# D1H.pdf register map
Vendor: Allwinner; Series: D1H.pdf; File version: 0.1
CPU: XuanTie C906 RISC-V CPU 0, little endian, MPU, FPU, double-precision FPU, 0 interrupt priority bits
Registers are 32-bit, read-write, reset 0x0 unless marked. A register's access mark holds for its fields unless they carry their own. Offsets are from the block's base; [hi:lo] are bit positions; lines under a group give offsets from that group; {n}, {i} and the like mark numbered series.

## TVD_TOP
Base 0x05C00000
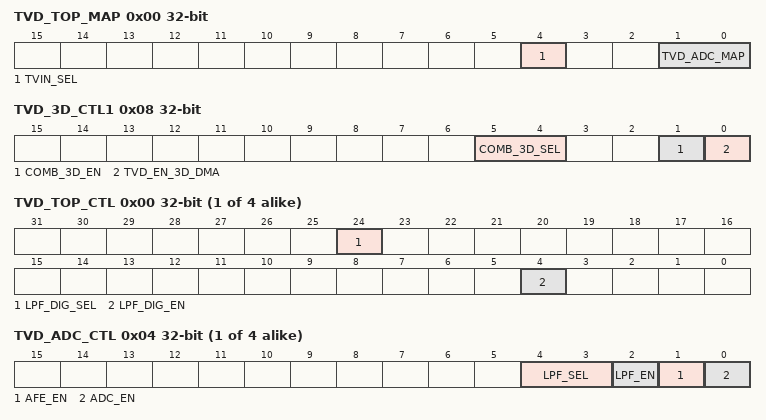
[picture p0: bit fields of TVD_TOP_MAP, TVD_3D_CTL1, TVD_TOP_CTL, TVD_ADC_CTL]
0x00 TVD_TOP_MAP
  [4] TVIN_SEL — TVIN Select 0:TVIN0 1:TVIN1
  [1:0] TVD_ADC_MAP — TVD ADC Map 01: CVBS_MODE Others: Reserved
    1=CVBS_MODE
0x08 TVD_3D_CTL1 — TVD 3D DMA CONTROL Register1
  [5:4] COMB_3D_SEL — Comb 3D Select 00: TVD0 Others: Reserved
    0=TVD0
  [1] COMB_3D_EN — Comb 3D Enable 0: Disable 1: Enable
    0=Disable; 1=Enable
  [0] TVD_EN_3D_DMA — TVD Enable 3D DMA 0: Disable 1: Enable Set 0x1 when enable 3D comb filter.
    0=Disable; 1=Enable Set 0x1 when enable 3D comb filter
0x0C TVD_3D_CTL2 — TVD 3D DMA CONTROL Register2
  [31:0] DRAM_TRIG — DRAM Trigger
0x10 TVD_3D_CTL3 — TVD 3D DMA CONTROL Register3
  [31:0] COMB_3D_ADDR0 — Comb 3D Address0
0x14 TVD_3D_CTL4 — TVD 3D DMA CONTROL Register4
  [31:0] COMB_3D_ADDR1 — Comb 3D Address1
0x18 TVD_3D_CTL5 — TVD 3D DMA CONTROL Register5
  [31:0] COMB_3D_SIZE
{0x24+0x20*i} _N[{i}] (i=0..3) group
  0x00 TVD_TOP_CTL — TVD TOP CONTROL Register
    [24] LPF_DIG_SEL — Low Pass Filter Digital Select 0: 6M 1: 8M
      0=_6M; 1=_8M
    [4] LPF_DIG_EN — Low Pass Filter Digital Enable 0: Disable 1: Enable
      0=Disable; 1=Enable
  0x04 TVD_ADC_CTL — TVD ADC CONTROL Register
    [4:3] LPF_SEL — Low Pass Filter Select 00: 11M 01: 16M
      0=_11M; 1=_16M
    [2] LPF_EN — Low Pass Filter Enable 0: Disable LPF circuit 1: Enable LPF circuit
      0=Disable LPF circuit; 1=Enable LPF circuit
    [1] AFE_EN — AFE Enable 0: Disable AFE circuit 1: Enable AFE circuit
      0=Disable AFE circuit; 1=Enable AFE circuit
    [0] ADC_EN — ADC Enable 0: Disable ADC circuit 1: Enable ADC circuit
      0=Disable ADC circuit; 1=Enable ADC circuit
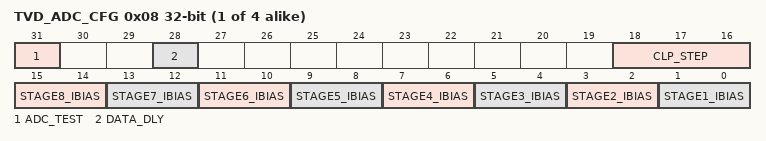
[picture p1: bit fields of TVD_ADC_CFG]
  0x08 TVD_ADC_CFG — TVD ADC CONFIGURATION Register
    [31] ADC_TEST — ADC Test Mode Configuration 0: Normal mode 1: For ADC test
      0=Normal_mode; 1=For (For ADC test)
    [28] DATA_DLY — Data Delay Configuration 0: No delay 1: Delay ADC output data for half circle
      0=No_delay; 1=Delay ADC output data for half circle
    [18:16] CLP_STEP — CLAMP Step Configuration DC level size step for up and down.
    [2n-1:2n-2] STAGE{n}_IBIAS (n=1..8) — Stage{n} Ibias Configuration

## TVE_TOP
Base 0x05600000
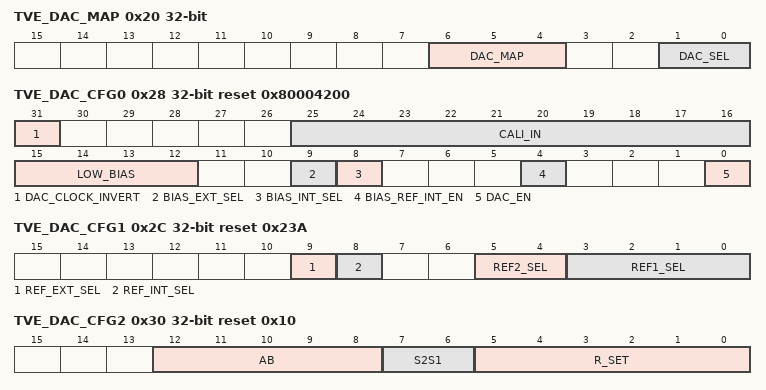
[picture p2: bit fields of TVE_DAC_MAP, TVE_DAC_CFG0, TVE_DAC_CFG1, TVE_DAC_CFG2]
0x20 TVE_DAC_MAP — TV Encoder DAC MAP Register
  [6:4] DAC_MAP — 000: OUT0 Others: Reserved
    0=OUT0
  [1:0] DAC_SEL — 00: Reserved 01: TVE0 10: Reserved 11: Reserved
    1=TVE0
0x24 TVE_DAC_STATUS — TV Encoder DAC STAUTS Register
  [1:0] DAC_STATUS ro — 00: Unconnected 01: Connected 11: Short to ground 10: Reserved
    0=Unconnected; 1=Connected; 3=Short to ground
0x28 TVE_DAC_CFG0 reset 0x80004200 — TV Encoder DAC CFG0 Register
  [31] DAC_CLOCK_INVERT — 0: Not invert 1: Invert
    0=Not_invert; 1=Invert
  [25:16] CALI_IN
  [15:12] LOW_BIAS — 500 uA to 4 mA
  [9] BIAS_EXT_SEL — 0: Disable 1: Enable (A_SEL_BIAS_ADDA)
    0=Disable; 1=Enable (A_SEL_BIAS_ADDA)
  [8] BIAS_INT_SEL — 0: Disable 1: Enable (A_SEL_BIAS_RES)
    0=Disable; 1=Enable (A_SEL_BIAS_RES)
  [4] BIAS_REF_INT_EN — 0: Disable 1: Enable (A_EN_RESREF)
    0=Disable; 1=Enable (A_EN_RESREF)
  [0] DAC_EN — 0: Disable 1: Enable
    0=Disable; 1=Enable
0x2C TVE_DAC_CFG1 reset 0x23A — TV Encoder DAC CFG1 Register
  [9] REF_EXT_SEL — 0: Disable 1: Enable (A_SEL_DETREF_LDO)
    0=Disable; 1=Enable (A_SEL_DETREF_LDO)
  [8] REF_INT_SEL — 0: Disable 1: Enable (A_SEL_DETREF_RES)
    0=Disable; 1=Enable (A_SEL_DETREF_RES)
  [5:4] REF2_SEL — 00: 0.25 V 01: 0.30 V 10: 0.35 V 11: 0.40 V (a_refslct2<1:0>)
    0=_0_point_25_V (0.25 V); 1=_0_point_30_V (0.30 V); 2=_0_point_35_V (0.35 V); 3=_0_point_40_V (0.40 V (a_refslct2<1:0>))
  [3:0] REF1_SEL — 0000: 0.50 V 0001: 0.55 V 0010: 0.60 V 0011: 0.65 V 0100: 0.70 V 0101: 0.75 V 0110: 0.80 V 0111: 0.85 V 1000: 0.90 V 1001: 0.95 V 1010: 1.00 V 1011: 1.05 V 1100: 1.10 V 1101: 1.15 V 1110: 1.20 V 1111: 1.25 V (a_refslct1<3:0>) The reference voltage is used for hot plug detect function.
    0=_0_point_50_V (0.50 V); 1=_0_point_55_V (0.55 V); 2=_0_point_60_V (0.60 V); 3=_0_point_65_V (0.65 V); 4=_0_point_70_V (0.70 V); 5=_0_point_75_V (0.75 V); 6=_0_point_80_V (0.80 V); 7=_0_point_85_V (0.85 V); 8=_0_point_90_V (0.90 V); 9=_0_point_95_V (0.95 V); 10=_1_point_00_V (1.00 V); 11=_1_point_05_V (1.05 V); 12=_1_point_10_V (1.10 V); 13=_1_point_15_V (1.15 V); 14=_1_point_20_V (1.20 V); 15=_1_point_25_V (1.25 V (a_refslct1<3:0>) The reference voltage is used for hot plug detect function.)
0x30 TVE_DAC_CFG2 reset 0x10 — TV Encoder DAC CFG2 Register
  [12:8] AB — ( I config output current for different peak voltage)
  [7:6] S2S1
  [5:0] R_SET
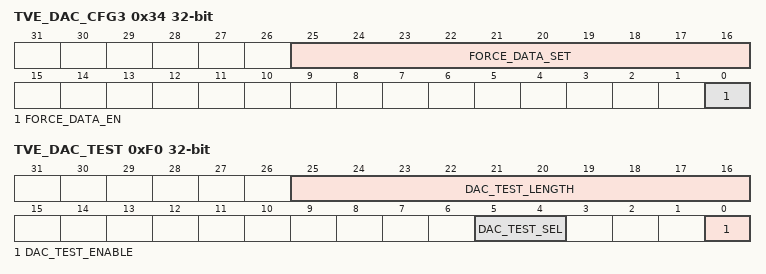
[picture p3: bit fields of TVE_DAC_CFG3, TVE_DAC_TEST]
0x34 TVE_DAC_CFG3 — TV Encoder DAC CFG2 Register
  [25:16] FORCE_DATA_SET — Force DAC input data
  [0] FORCE_DATA_EN — 0: DAC input data from TVE 1: DAC input data from FORCE_DATA_SET
    0=DAC_input_data_from_TVE; 1=DAC_input_data_from_FORCE_DATA_SET
0xF0 TVE_DAC_TEST — TV Encoder DAC TEST Register
  [25:16] DAC_TEST_LENGTH — DAC TEST DATA LENGTH
  [5:4] DAC_TEST_SEL — 00: DAC0 Others: Reserved
    0=DAC0
  [0] DAC_TEST_ENABLE — 0: Reserved 1: Repeat DAC data from DAC sram
    1=Repeat DAC data from DAC sram
